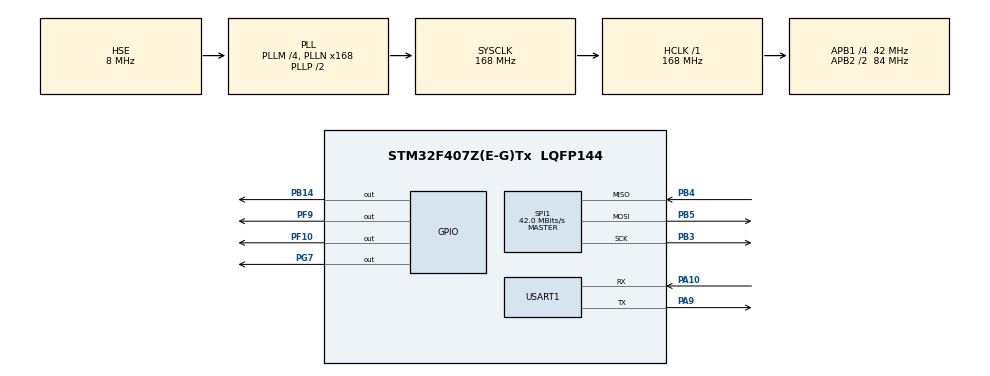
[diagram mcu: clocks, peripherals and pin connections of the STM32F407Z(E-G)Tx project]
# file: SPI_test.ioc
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Mcu.Family=STM32F4
Mcu.Name=STM32F407Z(E-G)Tx
Mcu.Package=LQFP144
NVIC.PriorityGroup=NVIC_PRIORITYGROUP_4
PA10.Mode=Asynchronous
PA10.Signal=USART1_RX
PA13.Mode=Serial_Wire
PA13.Signal=SYS_JTMS-SWDIO
PA14.Mode=Serial_Wire
PA14.Signal=SYS_JTCK-SWCLK
PA9.Mode=Asynchronous
PA9.Signal=USART1_TX
PB14.PinState=GPIO_PIN_SET
PB14.Signal=GPIO_Output
PB3.Mode=Full_Duplex_Master
PB3.Signal=SPI1_SCK
PB4.Mode=Full_Duplex_Master
PB4.Signal=SPI1_MISO
PB5.Mode=Full_Duplex_Master
PB5.Signal=SPI1_MOSI
PF10.PinState=GPIO_PIN_SET
PF10.Signal=GPIO_Output
PF9.PinState=GPIO_PIN_SET
PF9.Signal=GPIO_Output
PG7.PinState=GPIO_PIN_SET
PG7.Signal=GPIO_Output
PH0-OSC_IN.Mode=HSE-External-Oscillator
PH0-OSC_IN.Signal=RCC_OSC_IN
PH1-OSC_OUT.Mode=HSE-External-Oscillator
PH1-OSC_OUT.Signal=RCC_OSC_OUT
ProjectManager.HeapSize=0x200
ProjectManager.StackSize=0x400
ProjectManager.TargetToolchain=MDK-ARM V5.32
RCC.48MHZClocksFreq_Value=84000000
RCC.AHBFreq_Value=168000000
RCC.APB1CLKDivider=RCC_HCLK_DIV4
RCC.APB1Freq_Value=42000000
RCC.APB1TimFreq_Value=84000000
RCC.APB2CLKDivider=RCC_HCLK_DIV2
RCC.APB2Freq_Value=84000000
RCC.APB2TimFreq_Value=168000000
RCC.CortexFreq_Value=168000000
RCC.HCLKFreq_Value=168000000
RCC.HSE_VALUE=8000000
RCC.HSI_VALUE=16000000
RCC.LSE_VALUE=32768
RCC.PLLM=4
RCC.PLLN=168
RCC.PLLSourceVirtual=RCC_PLLSOURCE_HSE
RCC.SYSCLKFreq_VALUE=168000000
RCC.SYSCLKSource=RCC_SYSCLKSOURCE_PLLCLK
RCC.VCOOutputFreq_Value=336000000
SPI1.CalculateBaudRate=42.0 MBits/s
SPI1.Direction=SPI_DIRECTION_2LINES
SPI1.Mode=SPI_MODE_MASTER
SPI1.VirtualType=VM_MASTER
USART1.Parity=PARITY_ODD
USART1.VirtualMode=VM_ASYNC
USART1.WordLength=WORDLENGTH_9B
board=custom

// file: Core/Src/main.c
/* USER CODE BEGIN Header */
/**
  ******************************************************************************
  * @file           : main.c
  * @brief          : Main program body
  ******************************************************************************
  * @attention
  *
  * Copyright (c) 2026 STMicroelectronics.
  * All rights reserved.
  *
  * This software is licensed under terms that can be found in the LICENSE file
  * in the root directory of this software component.
  * If no LICENSE file comes with this software, it is provided AS-IS.
  *
  ******************************************************************************
  */
/* USER CODE END Header */
#include "main.h"

/* USER CODE BEGIN Includes */
#include "apptest.h"
/* USER CODE END Includes */

SPI_HandleTypeDef hspi1;

UART_HandleTypeDef huart1;

void SystemClock_Config(void);
static void MX_GPIO_Init(void);
static void MX_SPI1_Init(void);
static void MX_USART1_UART_Init(void);

int main(void)
{

  /* MCU Configuration--------------------------------------------------------*/

  /* Reset of all peripherals, Initializes the Flash interface and the Systick. */
  HAL_Init();

  /* Configure the system clock */
  SystemClock_Config();

  /* Initialize all configured peripherals */
  MX_GPIO_Init();
  MX_SPI1_Init();
  MX_USART1_UART_Init();
  /* USER CODE BEGIN 2 */
  BSP_Usart_Init(&huart1);
  /* USER CODE END 2 */

  /* Infinite loop */
  /* USER CODE BEGIN WHILE */
  Test_BSP_W25q128_Init(&hspi1);
  Test_BSP_W25q128_Read_Date();
  while (1)
  {
    /* USER CODE END WHILE */

  }
}

void SystemClock_Config(void)
{
  RCC_OscInitTypeDef RCC_OscInitStruct = {0};
  RCC_ClkInitTypeDef RCC_ClkInitStruct = {0};

  /** Configure the main internal regulator output voltage
  */
  __HAL_RCC_PWR_CLK_ENABLE();
  __HAL_PWR_VOLTAGESCALING_CONFIG(PWR_REGULATOR_VOLTAGE_SCALE1);

  /** Initializes the RCC Oscillators according to the specified parameters
  * in the RCC_OscInitTypeDef structure.
  */
  RCC_OscInitStruct.OscillatorType = RCC_OSCILLATORTYPE_HSE;
  RCC_OscInitStruct.HSEState = RCC_HSE_ON;
  RCC_OscInitStruct.PLL.PLLState = RCC_PLL_ON;
  RCC_OscInitStruct.PLL.PLLSource = RCC_PLLSOURCE_HSE;
  RCC_OscInitStruct.PLL.PLLM = 4;
  RCC_OscInitStruct.PLL.PLLN = 168;
  RCC_OscInitStruct.PLL.PLLP = RCC_PLLP_DIV2;
  RCC_OscInitStruct.PLL.PLLQ = 4;
  if (HAL_RCC_OscConfig(&RCC_OscInitStruct) != HAL_OK)
  {
    Error_Handler();
  }

  /** Initializes the CPU, AHB and APB buses clocks
  */
  RCC_ClkInitStruct.ClockType = RCC_CLOCKTYPE_HCLK|RCC_CLOCKTYPE_SYSCLK
                              |RCC_CLOCKTYPE_PCLK1|RCC_CLOCKTYPE_PCLK2;
  RCC_ClkInitStruct.SYSCLKSource = RCC_SYSCLKSOURCE_PLLCLK;
  RCC_ClkInitStruct.AHBCLKDivider = RCC_SYSCLK_DIV1;
  RCC_ClkInitStruct.APB1CLKDivider = RCC_HCLK_DIV4;
  RCC_ClkInitStruct.APB2CLKDivider = RCC_HCLK_DIV2;

  if (HAL_RCC_ClockConfig(&RCC_ClkInitStruct, FLASH_LATENCY_5) != HAL_OK)
  {
    Error_Handler();
  }
}

static void MX_SPI1_Init(void)
{

  /* SPI1 parameter configuration*/
  hspi1.Instance = SPI1;
  hspi1.Init.Mode = SPI_MODE_MASTER;
  hspi1.Init.Direction = SPI_DIRECTION_2LINES;
  hspi1.Init.DataSize = SPI_DATASIZE_8BIT;
  hspi1.Init.CLKPolarity = SPI_POLARITY_LOW;
  hspi1.Init.CLKPhase = SPI_PHASE_1EDGE;
  hspi1.Init.NSS = SPI_NSS_SOFT;
  hspi1.Init.BaudRatePrescaler = SPI_BAUDRATEPRESCALER_2;
  hspi1.Init.FirstBit = SPI_FIRSTBIT_MSB;
  hspi1.Init.TIMode = SPI_TIMODE_DISABLE;
  hspi1.Init.CRCCalculation = SPI_CRCCALCULATION_DISABLE;
  hspi1.Init.CRCPolynomial = 10;
  if (HAL_SPI_Init(&hspi1) != HAL_OK)
  {
    Error_Handler();
  }

}

static void MX_USART1_UART_Init(void)
{

  huart1.Instance = USART1;
  huart1.Init.BaudRate = 115200;
  huart1.Init.WordLength = UART_WORDLENGTH_9B;
  huart1.Init.StopBits = UART_STOPBITS_1;
  huart1.Init.Parity = UART_PARITY_ODD;
  huart1.Init.Mode = UART_MODE_TX_RX;
  huart1.Init.HwFlowCtl = UART_HWCONTROL_NONE;
  huart1.Init.OverSampling = UART_OVERSAMPLING_16;
  if (HAL_UART_Init(&huart1) != HAL_OK)
  {
    Error_Handler();
  }

}

static void MX_GPIO_Init(void)
{
  GPIO_InitTypeDef GPIO_InitStruct = {0};

  /* GPIO Ports Clock Enable */
  __HAL_RCC_GPIOF_CLK_ENABLE();
  __HAL_RCC_GPIOH_CLK_ENABLE();
  __HAL_RCC_GPIOB_CLK_ENABLE();
  __HAL_RCC_GPIOG_CLK_ENABLE();
  __HAL_RCC_GPIOA_CLK_ENABLE();

  /*Configure GPIO pin Output Level */
  HAL_GPIO_WritePin(GPIOF, GPIO_PIN_9|GPIO_PIN_10, GPIO_PIN_SET);

  /*Configure GPIO pin Output Level */
  HAL_GPIO_WritePin(GPIOB, GPIO_PIN_14, GPIO_PIN_SET);

  /*Configure GPIO pin Output Level */
  HAL_GPIO_WritePin(GPIOG, GPIO_PIN_7, GPIO_PIN_SET);

  /*Configure GPIO pins : PF9 PF10 */
  GPIO_InitStruct.Pin = GPIO_PIN_9|GPIO_PIN_10;
  GPIO_InitStruct.Mode = GPIO_MODE_OUTPUT_PP;
  GPIO_InitStruct.Pull = GPIO_NOPULL;
  GPIO_InitStruct.Speed = GPIO_SPEED_FREQ_LOW;
  HAL_GPIO_Init(GPIOF, &GPIO_InitStruct);

  /*Configure GPIO pin : PB14 */
  GPIO_InitStruct.Pin = GPIO_PIN_14;
  GPIO_InitStruct.Mode = GPIO_MODE_OUTPUT_PP;
  GPIO_InitStruct.Pull = GPIO_NOPULL;
  GPIO_InitStruct.Speed = GPIO_SPEED_FREQ_LOW;
  HAL_GPIO_Init(GPIOB, &GPIO_InitStruct);

  /*Configure GPIO pin : PG7 */
  GPIO_InitStruct.Pin = GPIO_PIN_7;
  GPIO_InitStruct.Mode = GPIO_MODE_OUTPUT_PP;
  GPIO_InitStruct.Pull = GPIO_NOPULL;
  GPIO_InitStruct.Speed = GPIO_SPEED_FREQ_LOW;
  HAL_GPIO_Init(GPIOG, &GPIO_InitStruct);

}

void Error_Handler(void)
{
  __disable_irq();
  while (1)
  {
  }
}
